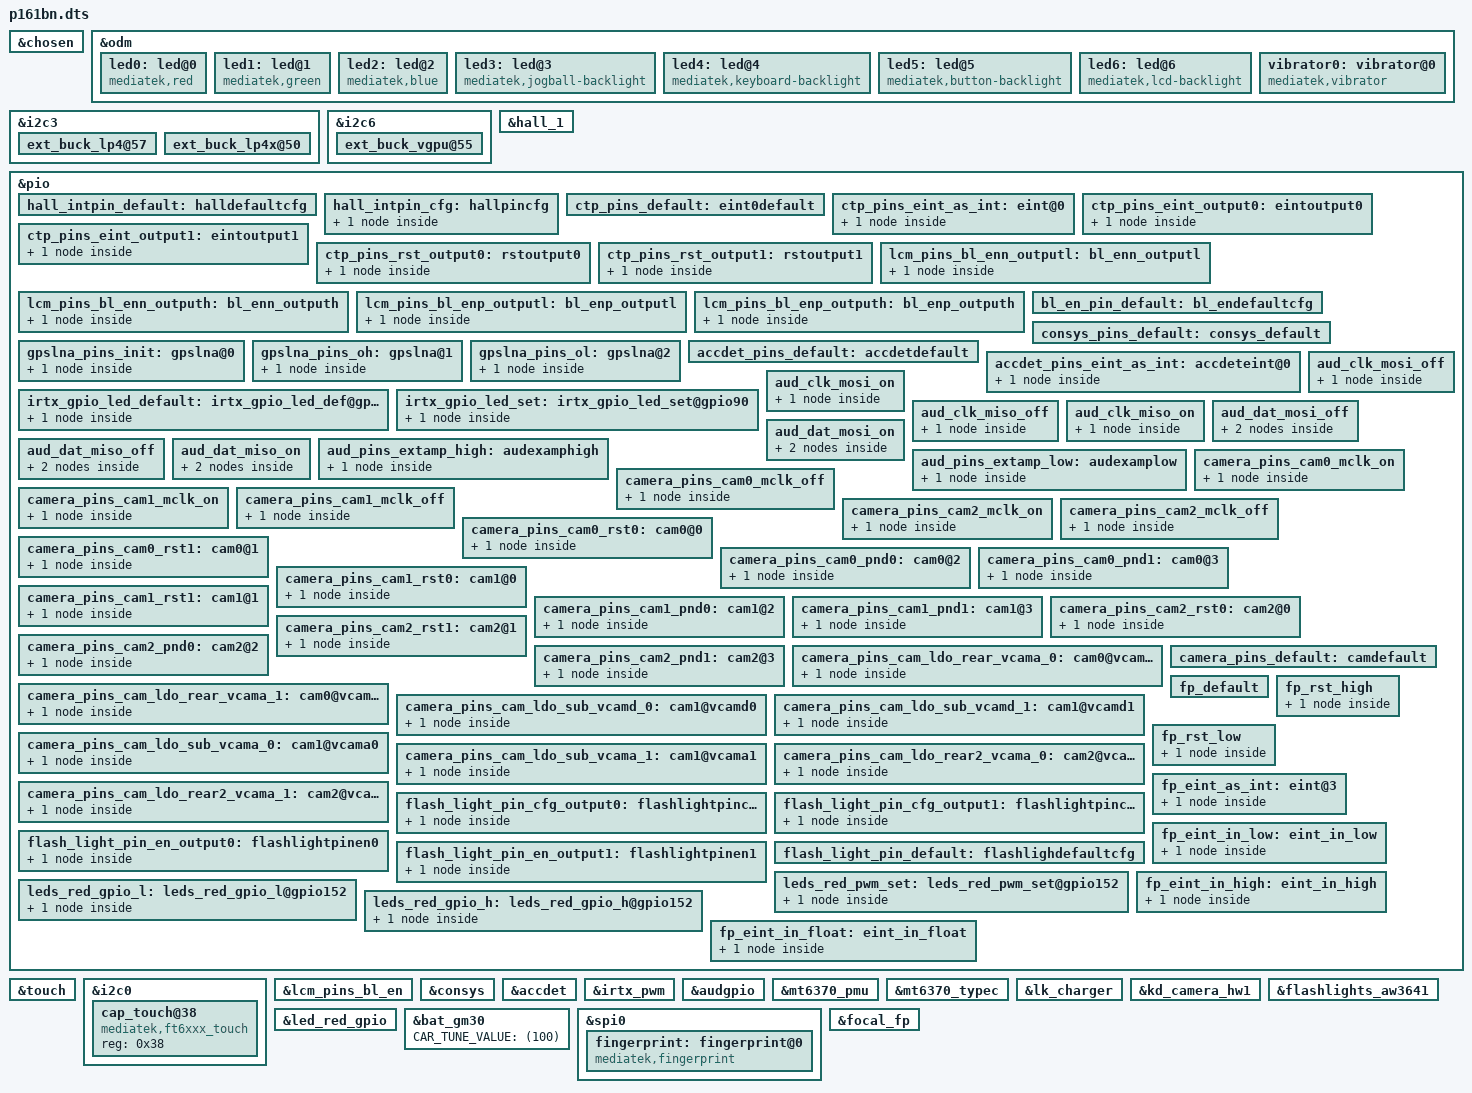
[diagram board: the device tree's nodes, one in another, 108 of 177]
#include <dt-bindings/interrupt-controller/arm-gic.h>
#include <dt-bindings/interrupt-controller/irq.h>
#include <dt-bindings/pinctrl/mt6765-pinfunc.h>
#include <dt-bindings/clock/mt6765-clk.h>

/dts-v1/;
/plugin/;

/* chosen */
&chosen {

	/* fpga may has no lk, we need to specify display info here */
	/* fb buffer is reserved using this dts by memory node above */
	atag,videolfb-fb_base_h = <0x0>;
	atag,videolfb-fb_base_l = <0x5e605000>;
	atag,videolfb-islcmfound = <1>;
	/* because no lk, so lcm is not inited */
	atag,videolfb-islcm_inited = <0>;
	atag,videolfb-fps= <6000>;
	atag,videolfb-vramSize= <0x017bb000>;
	atag,videolfb-lcmname= "nt35695B_fhd_dsi_cmd_auo_rt5081_drv";
};

&odm {
	led0:led@0 {
		compatible = "mediatek,red";
		led_mode = <1>;
		data = <2>;
		pwm_config = <0 0 0 0 0>;
	};
	led1:led@1 {
		compatible = "mediatek,green";
		led_mode = <3>;
		data = <2>;
		pwm_config = <0 0 0 0 0>;
	};
	led2:led@2 {
		compatible = "mediatek,blue";
		led_mode = <0>;
		data = <1>;
		pwm_config = <0 0 0 0 0>;
	};
	led3:led@3 {
		compatible = "mediatek,jogball-backlight";
		led_mode = <0>;
		data = <1>;
		pwm_config = <0 0 0 0 0>;
	};
	led4:led@4 {
		compatible = "mediatek,keyboard-backlight";
		led_mode = <0>;
		data = <1>;
		pwm_config = <0 0 0 0 0>;
	};
	led5:led@5 {
		compatible = "mediatek,button-backlight";
		led_mode = <0>;
		data = <1>;
		pwm_config = <0 0 0 0 0>;
	};
	led6:led@6 {
		compatible = "mediatek,lcd-backlight";
		led_mode = <5>;
		data = <1>;
		pwm_config = <0 0 0 0 0>;
	};
	vibrator0:vibrator@0 {
		compatible = "mediatek,vibrator";
		vib_timer = <25>;
		vib_limit = <9>;
		vib_vol= <9>; 			//1001 :2.8V,    1011 :3.0V,   1101 :3.3V
	};
};

&i2c3 {
	ext_buck_lp4@57 {
		regulator-name ="ext_buck_vdd2";
		regulator-min-microvolt = <300000>;
		regulator-max-microvolt = <1300000>;
		vsel_pin = <0>;
	};

	ext_buck_lp4x@50 {
		regulator-name ="ext_buck_vddq";
		regulator-min-microvolt = <300000>;
		regulator-max-microvolt = <1300000>;
		vsel_pin = <1>;
	};
};

&i2c6 {
	ext_buck_vgpu@55 {
		regulator-name ="ext_buck_vgpu";
		regulator-min-microvolt = <300000>;
		regulator-max-microvolt = <1300000>;
		vsel_pin = <2>;
	};
};


/*hall start*/

&hall_1 {
	pinctrl-names = "pin_default", "pin_cfg";
	pinctrl-0 = <&hall_intpin_default>;
	pinctrl-1 = <&hall_intpin_cfg>;
	status = "okay";
};
&pio {
	hall_intpin_default: halldefaultcfg {
	};
	hall_intpin_cfg: hallpincfg {
		pins_cmd_dat {
			pinmux = <PINMUX_GPIO9__FUNC_GPIO9>;
			slew-rate = <0>;
			bias-disable;
		};
	};
};
/*hall end*/

/* TOUCH start */
&touch {
	tpd-resolution = <720 1560>;
	use-tpd-button = <0>;
	tpd-key-num = <3>;
	tpd-key-local= <139 172 158 0>;
	tpd-key-dim-local = <90 883 100 40 230
				 883 100 40 370 883 100 40 0 0 0 0>;
	tpd-max-touch-num = <5>;
	tpd-filter-enable = <0>;
	tpd-filter-pixel-density = <146>;
	tpd-filter-custom-prameters = <0 0 0 0 0 0 0 0 0 0 0 0>;
	tpd-filter-custom-speed = <0 0 0>;
	pinctrl-names = "default", "state_eint_as_int", "state_eint_output0",
		"state_eint_output1", "state_rst_output0", "state_rst_output1";
	pinctrl-0 = <&ctp_pins_default>;
	pinctrl-1 = <&ctp_pins_eint_as_int>;
	pinctrl-2 = <&ctp_pins_eint_output0>;
	pinctrl-3 = <&ctp_pins_eint_output1>;
	pinctrl-4 = <&ctp_pins_rst_output0>;
	pinctrl-5 = <&ctp_pins_rst_output1>;
	status = "okay";
};
&pio {
	ctp_pins_default: eint0default {
	};
	ctp_pins_eint_as_int: eint@0 {
		pins_cmd_dat {
			pinmux = <PINMUX_GPIO0__FUNC_GPIO0>;
			slew-rate = <0>;
			bias-disable;
		};
	};
	ctp_pins_eint_output0: eintoutput0 {
		pins_cmd_dat {
			pinmux = <PINMUX_GPIO0__FUNC_GPIO0>;
			slew-rate = <1>;
			output-low;
		};
	};
	ctp_pins_eint_output1: eintoutput1 {
		pins_cmd_dat {
			pinmux = <PINMUX_GPIO0__FUNC_GPIO0>;
			slew-rate = <1>;
			output-high;
		};
	};
	ctp_pins_rst_output0: rstoutput0 {
		pins_cmd_dat {
			pinmux = <PINMUX_GPIO174__FUNC_GPIO174>;
			slew-rate = <1>;
			drive-strength = <MTK_DRIVE_16mA>;
			output-low;
		};
	};
	ctp_pins_rst_output1: rstoutput1 {
		pins_cmd_dat {
			pinmux = <PINMUX_GPIO174__FUNC_GPIO174>;
			slew-rate = <1>;
			output-high;
		};
	};
};

&i2c0 {
	cap_touch@38 {
		compatible = "mediatek,ft6xxx_touch";
		reg = <0x38>;
		status = "okay";
	};
};

/* TOUCH end */
&lcm_pins_bl_en {
	pinctrl-names = "bl_en_pin_default","lcm_enn_outputl","lcm_enn_outputh",
			"lcm_enp_outputl","lcm_enp_outputh";
	pinctrl-0 = <&bl_en_pin_default>;
	pinctrl-1 = <&lcm_pins_bl_enn_outputl>;
	pinctrl-2 = <&lcm_pins_bl_enn_outputh>;
	pinctrl-3 = <&lcm_pins_bl_enp_outputl>;
	pinctrl-4 = <&lcm_pins_bl_enp_outputh>;
	
	status = "okay";
};
&pio {
	lcm_pins_bl_enn_outputl: bl_enn_outputl {
		pins_cmd_dat {
			pinmux = <PINMUX_GPIO176__FUNC_GPIO176>;
			slew-rate = <1>;
			output-low;
		};
	};

	lcm_pins_bl_enn_outputh: bl_enn_outputh {
		pins_cmd_dat {
			pinmux = <PINMUX_GPIO176__FUNC_GPIO176>;
			slew-rate = <1>;
			output-high;
		};
	};
	lcm_pins_bl_enp_outputl: bl_enp_outputl {
		pins_cmd_dat {
			pinmux = <PINMUX_GPIO177__FUNC_GPIO177>;
			slew-rate = <1>;
			output-low;
		};
	};

	lcm_pins_bl_enp_outputh: bl_enp_outputh {
		pins_cmd_dat {
			pinmux = <PINMUX_GPIO177__FUNC_GPIO177>;
			slew-rate = <1>;
			output-high;
		};
	};
	
	bl_en_pin_default: bl_endefaultcfg {
	};
};

/* CONSYS GPIO standardization */
&pio {
	consys_pins_default: consys_default {
	};
	gpslna_pins_init: gpslna@0 {
		pins_cmd_dat {
			pinmux = <PINMUX_GPIO91__FUNC_GPIO91>;
			slew-rate = <0>;
			bias-disable;
			output-low;
		};
	};
	gpslna_pins_oh: gpslna@1 {
		pins_cmd_dat {
			pinmux = <PINMUX_GPIO91__FUNC_GPIO91>;
			slew-rate = <1>;
			output-high;
		};
	};
	gpslna_pins_ol: gpslna@2 {
		pins_cmd_dat {
			pinmux = <PINMUX_GPIO91__FUNC_GPIO91>;
			slew-rate = <1>;
			output-low;
		};
	};
};
&consys {
	pinctrl-names = "default", "gps_lna_state_init",
		"gps_lna_state_oh", "gps_lna_state_ol";
	pinctrl-0 = <&consys_pins_default>;
	pinctrl-1 = <&gpslna_pins_init>;
	pinctrl-2 = <&gpslna_pins_oh>;
	pinctrl-3 = <&gpslna_pins_ol>;
	status = "okay";
};
/* CONSYS end */

/* accdet start */
&accdet {
	accdet-mic-vol = <6>;
	headset-mode-setting = <0x500 0x500 1 0x1f0 0x800 0x800 0x20 0x44>;
	accdet-plugout-debounce = <1>;
	accdet-mic-mode = <1>;
	headset-eint-level-pol = <8>;
	headset-three-key-threshold = <0 80 220 400>;
	headset-three-key-threshold-CDD = <0 121 192 600>;
	headset-four-key-threshold = <0 58 121 192 400>;
	pinctrl-names = "default", "state_eint_as_int";
	pinctrl-0 = <&accdet_pins_default>;
	pinctrl-1 = <&accdet_pins_eint_as_int>;
	status = "okay";
};
&pio {
	accdet_pins_default: accdetdefault {
	};
	accdet_pins_eint_as_int: accdeteint@0 {
		pins_cmd_dat {
			pinmux = <PINMUX_GPIO9__FUNC_GPIO9>;
			slew-rate = <0>;
			bias-disable;
		};
	};
};
/* accdet end */


/* IRTX GPIO end */
&irtx_pwm {
	pinctrl-names = "irtx_gpio_led_default", "irtx_gpio_led_set";
	pinctrl-0 = <&irtx_gpio_led_default>;
	pinctrl-1 = <&irtx_gpio_led_set>;
	status = "okay";
};
&pio {
	irtx_gpio_led_default:irtx_gpio_led_def@gpio90 {
		pins_cmd_dat {
			pinmux = <PINMUX_GPIO90__FUNC_GPIO90>;
			slew-rate = <1>;
			bias-disable;
			output-low;
			input-schmitt-enable = <0>;
		};
	};

	irtx_gpio_led_set:irtx_gpio_led_set@gpio90 {
		pins_cmd_dat {
			pinmux = <PINMUX_GPIO90__FUNC_PWM0>;
			slew-rate = <1>;
			output-high;
		};
	};
};
/* IRTX GPIO Settings -End */

/* AUDIO GPIO standardization */
&audgpio {
	pinctrl-names = "aud_clk_mosi_off",
			"aud_clk_mosi_on",
			"aud_clk_miso_off",
			"aud_clk_miso_on",
			"aud_dat_mosi_off",
			"aud_dat_mosi_on",
			"aud_dat_miso_off",
			"aud_dat_miso_on",
			"extamp-pullhigh",
			"extamp-pulllow";
	pinctrl-0 = <&aud_clk_mosi_off>;
	pinctrl-1 = <&aud_clk_mosi_on>;
	pinctrl-2 = <&aud_clk_miso_off>;
	pinctrl-3 = <&aud_clk_miso_on>;
	pinctrl-4 = <&aud_dat_mosi_off>;
	pinctrl-5 = <&aud_dat_mosi_on>;
	pinctrl-6 = <&aud_dat_miso_off>;
	pinctrl-7 = <&aud_dat_miso_on>;
	pinctrl-8 = <&aud_pins_extamp_high>;
	pinctrl-9 = <&aud_pins_extamp_low>;
	status = "okay";
};

&pio {
	aud_clk_mosi_off: aud_clk_mosi_off {
		pins_cmd0_dat {
			pinmux = <PINMUX_GPIO136__FUNC_GPIO136>;
		};
	};

	aud_clk_mosi_on: aud_clk_mosi_on {
		pins_cmd0_dat {
			pinmux = <PINMUX_GPIO136__FUNC_AUD_CLK_MOSI>;
		};
	};

	aud_clk_miso_off: aud_clk_miso_off {
		pins_cmd0_dat {
			pinmux = <PINMUX_GPIO140__FUNC_GPIO140>;
		};
	};

	aud_clk_miso_on: aud_clk_miso_on {
		pins_cmd0_dat {
			pinmux = <PINMUX_GPIO140__FUNC_AUD_CLK_MISO>;
		};
	};

	aud_dat_mosi_off: aud_dat_mosi_off {
		pins_cmd1_dat {
			pinmux = <PINMUX_GPIO138__FUNC_GPIO138>;
			input-enable;
			slew-rate = <0>;
			bias-disable;
		};
		pins_cmd2_dat {
			pinmux = <PINMUX_GPIO139__FUNC_GPIO139>;
			input-enable;
			slew-rate = <0>;
			bias-disable;
		};
	};

	aud_dat_mosi_on: aud_dat_mosi_on {
		pins_cmd1_dat {
			pinmux = <PINMUX_GPIO138__FUNC_AUD_DAT_MOSI0>;
		};
		pins_cmd2_dat {
			pinmux = <PINMUX_GPIO139__FUNC_AUD_DAT_MOSI1>;
		};
	};

	aud_dat_miso_off: aud_dat_miso_off {
		pins_cmd1_dat {
			pinmux = <PINMUX_GPIO142__FUNC_GPIO142>;
			input-enable;
			slew-rate = <0>;
			bias-disable;
		};
		pins_cmd2_dat {
			pinmux = <PINMUX_GPIO143__FUNC_GPIO143>;
			input-enable;
			slew-rate = <0>;
			bias-disable;
		};
	};

	aud_dat_miso_on: aud_dat_miso_on {
		pins_cmd1_dat {
			pinmux = <PINMUX_GPIO142__FUNC_AUD_DAT_MISO0>;
		};
		pins_cmd2_dat {
			pinmux = <PINMUX_GPIO143__FUNC_AUD_DAT_MISO1>;
		};
	};

	aud_pins_extamp_high: audexamphigh {
		pins_cmd_dat {
			pinmux = <PINMUX_GPIO159__FUNC_GPIO159>;
			slew-rate = <1>;
			output-high;
		};
	};

	aud_pins_extamp_low: audexamplow {
		pins_cmd_dat {
			pinmux = <PINMUX_GPIO159__FUNC_GPIO159>;
			slew-rate = <1>;
			output-low;
		};
	};
};
/* AUDIO end */

&mt6370_pmu {
	mt6370,intr_gpio_num = <11>; /* direct defined GPIO num */
	mt6370,intr_gpio = <&pio 11 0x0>;
};

&mt6370_typec {
	mt6370pd,intr_gpio_num = <41>; /* direct defined GPIO num */
	mt6370pd,intr_gpio = <&pio 41 0x0>;
};

&lk_charger {
	fast_charge_voltage = <3000000>;
	/* charging current */
	usb_charger_current = <500000>;
	ac_charger_current = <550000>;
	ac_charger_input_current = <550000>;
	non_std_ac_charger_current = <550000>;
	charging_host_charger_current = <550000>;
	ta_ac_charger_current = <3000000>;
	pd_charger_current = <500000>;
//	enable_anime = <0>;

	/* battery temperature protection */
		temp_t4_threshold = <57>;
		temp_t3_threshold = <45>;
		temp_t1_threshold = <3>;
};

&pio {
	camera_pins_cam0_mclk_on: camera_pins_cam0_mclk_on {
		pins_cmd_dat {
			pinmux = <PINMUX_GPIO99__FUNC_CMMCLK0>;
		};
	};
	camera_pins_cam0_mclk_off: camera_pins_cam0_mclk_off {
		pins_cmd_dat {
			pinmux = <PINMUX_GPIO99__FUNC_GPIO99>;
		};
	};
	camera_pins_cam1_mclk_on: camera_pins_cam1_mclk_on {
		pins_cmd_dat {
			pinmux = <PINMUX_GPIO100__FUNC_CMMCLK1>;
		};
	};
	camera_pins_cam1_mclk_off: camera_pins_cam1_mclk_off {
		pins_cmd_dat {
			pinmux = <PINMUX_GPIO100__FUNC_GPIO100>;
		};
	};
	camera_pins_cam2_mclk_on: camera_pins_cam2_mclk_on {
		pins_cmd_dat {
			pinmux = <PINMUX_GPIO108__FUNC_CMMCLK2>;
		};
	};
	camera_pins_cam2_mclk_off: camera_pins_cam2_mclk_off {
		pins_cmd_dat {
			pinmux = <PINMUX_GPIO108__FUNC_GPIO108>;
		};
	};
	camera_pins_cam0_rst0: cam0@0 {
		pins_cmd_dat {
			pinmux = <PINMUX_GPIO101__FUNC_GPIO101>;
			slew-rate = <1>;
			output-low;
		};
	};
	camera_pins_cam0_rst1: cam0@1 {
		pins_cmd_dat {
			pinmux = <PINMUX_GPIO101__FUNC_GPIO101>;
			slew-rate = <1>;
			output-high;
		};
	};
	camera_pins_cam0_pnd0: cam0@2 {
		pins_cmd_dat {
			pinmux = <PINMUX_GPIO97__FUNC_GPIO97>;
			slew-rate = <1>;
			output-low;
		};
	};
	camera_pins_cam0_pnd1: cam0@3 {
		pins_cmd_dat {
			pinmux = <PINMUX_GPIO97__FUNC_GPIO97>;
			slew-rate = <1>;
			output-high;
		};
	};
	camera_pins_cam1_rst0: cam1@0 {
		pins_cmd_dat {
			pinmux = <PINMUX_GPIO102__FUNC_GPIO102>;
			slew-rate = <1>;
			output-low;
		};
	};
	camera_pins_cam1_rst1: cam1@1 {
		pins_cmd_dat {
			pinmux = <PINMUX_GPIO102__FUNC_GPIO102>;
			slew-rate = <1>;
			output-high;
		};
	};
	camera_pins_cam1_pnd0: cam1@2 {
		pins_cmd_dat {
			pinmux = <PINMUX_GPIO98__FUNC_GPIO98>;
			slew-rate = <1>;
			output-low;
		};
	};
	camera_pins_cam1_pnd1: cam1@3 {
		pins_cmd_dat {
			pinmux = <PINMUX_GPIO98__FUNC_GPIO98>;
			slew-rate = <1>;
			output-high;
		};
	};
	camera_pins_cam2_rst0: cam2@0 {
		pins_cmd_dat {
			pinmux = <PINMUX_GPIO109__FUNC_GPIO109>;
			slew-rate = <1>;
			output-low;
		};
	};
	camera_pins_cam2_rst1: cam2@1 {
		pins_cmd_dat {
			pinmux = <PINMUX_GPIO109__FUNC_GPIO109>;
			slew-rate = <1>;
			output-high;
		};
	};
	camera_pins_cam2_pnd0: cam2@2 {
		pins_cmd_dat {
			pinmux = <PINMUX_GPIO107__FUNC_GPIO107>;
			slew-rate = <1>;
			output-low;
		};
	};
	camera_pins_cam2_pnd1: cam2@3 {
		pins_cmd_dat {
			pinmux = <PINMUX_GPIO107__FUNC_GPIO107>;
			slew-rate = <1>;
			output-high;
		};
	};
	camera_pins_cam_ldo_rear_vcama_0: cam0@vcamd0 {
		pins_cmd_dat {
			pinmux = <PINMUX_GPIO168__FUNC_GPIO168>;
			slew-rate = <1>;
			output-low;
		};
	};
	camera_pins_cam_ldo_rear_vcama_1: cam0@vcamd1 {
		pins_cmd_dat {
			pinmux = <PINMUX_GPIO168__FUNC_GPIO168>;
			slew-rate = <1>;
			output-high;
		};
	};
	camera_pins_cam_ldo_sub_vcamd_0: cam1@vcamd0 {
		pins_cmd_dat {
			pinmux = <PINMUX_GPIO92__FUNC_GPIO92>;
			slew-rate = <1>;
			output-low;
		};
	};
	camera_pins_cam_ldo_sub_vcamd_1: cam1@vcamd1 {
		pins_cmd_dat {
			pinmux = <PINMUX_GPIO92__FUNC_GPIO92>;
			slew-rate = <1>;
			output-high;
		};
	};
	camera_pins_cam_ldo_sub_vcama_0: cam1@vcama0 {
		pins_cmd_dat {
			pinmux = <PINMUX_GPIO168__FUNC_GPIO168>;
			slew-rate = <1>;
			output-low;
		};
	};
	camera_pins_cam_ldo_sub_vcama_1: cam1@vcama1 {
		pins_cmd_dat {
			pinmux = <PINMUX_GPIO168__FUNC_GPIO168>;
			slew-rate = <1>;
			output-high;
		};
	};
	camera_pins_cam_ldo_rear2_vcama_0: cam2@vcama0 {
		pins_cmd_dat {
			pinmux = <PINMUX_GPIO168__FUNC_GPIO168>;
			slew-rate = <1>;
			output-low;
		};
	};
	camera_pins_cam_ldo_rear2_vcama_1: cam2@vcama1 {
		pins_cmd_dat {
			pinmux = <PINMUX_GPIO168__FUNC_GPIO168>;
			slew-rate = <1>;
			output-high;
		};
	};
	camera_pins_default: camdefault {
	};

};

&kd_camera_hw1 {
	pinctrl-names = "default",
			"cam0_rst0",
			"cam0_rst1",
			"cam0_pnd0",
			"cam0_pnd1",
			"cam1_rst0",
			"cam1_rst1",
			"cam1_pnd0",
			"cam1_pnd1",
			"cam2_rst0",
			"cam2_rst1",
			"cam2_pnd0",
			"cam2_pnd1",
			"cam0_vcama_on",
			"cam0_vcama_off",
			"cam1_vcamd_on",
			"cam1_vcamd_off",
			"cam1_vcama_on",
			"cam1_vcama_off",
			"cam2_vcama_on",
			"cam2_vcama_off",
			"cam0_mclk_on",
			"cam0_mclk_off",
			"cam1_mclk_on",
			"cam1_mclk_off",
			"cam2_mclk_on",
			"cam2_mclk_off";

	pinctrl-0 = <&camera_pins_default>;
	pinctrl-1 = <&camera_pins_cam0_rst0>;
	pinctrl-2 = <&camera_pins_cam0_rst1>;
	pinctrl-3 = <&camera_pins_cam0_pnd0>;
	pinctrl-4 = <&camera_pins_cam0_pnd1>;
	pinctrl-5 = <&camera_pins_cam1_rst0>;
	pinctrl-6 = <&camera_pins_cam1_rst1>;
	pinctrl-7 = <&camera_pins_cam1_pnd0>;
	pinctrl-8 = <&camera_pins_cam1_pnd1>;
	pinctrl-9 = <&camera_pins_cam2_rst0>;
	pinctrl-10 = <&camera_pins_cam2_rst1>;
	pinctrl-11 = <&camera_pins_cam2_pnd0>;
	pinctrl-12 = <&camera_pins_cam2_pnd1>;
	pinctrl-13 = <&camera_pins_cam_ldo_rear_vcama_1>;
	pinctrl-14 = <&camera_pins_cam_ldo_rear_vcama_0>;
	pinctrl-15 = <&camera_pins_cam_ldo_sub_vcamd_1>;
	pinctrl-16 = <&camera_pins_cam_ldo_sub_vcamd_0>;
	pinctrl-17 = <&camera_pins_cam_ldo_sub_vcama_1>;
	pinctrl-18 = <&camera_pins_cam_ldo_sub_vcama_0>;
	pinctrl-19 = <&camera_pins_cam_ldo_rear2_vcama_1>;
	pinctrl-20 = <&camera_pins_cam_ldo_rear2_vcama_0>;
	pinctrl-21 = <&camera_pins_cam0_mclk_on>;
	pinctrl-22 = <&camera_pins_cam0_mclk_off>;
	pinctrl-23 = <&camera_pins_cam1_mclk_on>;
	pinctrl-24 = <&camera_pins_cam1_mclk_off>;
	pinctrl-25 = <&camera_pins_cam2_mclk_on>;
	pinctrl-26 = <&camera_pins_cam2_mclk_off>;
	status = "okay";

};

/*add for aw3641 driver for camera flashlight*/
&pio {
        flash_light_pin_cfg_output0: flashlightpincfg0 {
            pins_cmd_dat {
                        pinmux = <PINMUX_GPIO153__FUNC_GPIO153>;
                        slew-rate = <1>;
                        output-low;
                };
        };
        flash_light_pin_cfg_output1: flashlightpincfg1 {
            pins_cmd_dat {
                        pinmux = <PINMUX_GPIO153__FUNC_GPIO153>;
                        slew-rate = <1>;
                        output-high;
                };
        };
        flash_light_pin_en_output0: flashlightpinen0 {
            pins_cmd_dat {
                        pinmux = <PINMUX_GPIO151__FUNC_GPIO151>;
                        slew-rate = <1>;
                        output-low;
                };
        };
        flash_light_pin_en_output1: flashlightpinen1 {
            pins_cmd_dat {
                        pinmux = <PINMUX_GPIO151__FUNC_GPIO151>;
                        slew-rate = <1>;
                        output-high;
                };
        };
         flash_light_pin_default: flashlighdefaultcfg {
        };

};

&flashlights_aw3641 {
        pinctrl-names = "flashlightpin_default", "flashlightpin_cfg0", "flashlightpin_cfg1","flashlightpin_en0","flashlightpin_en1";
        pinctrl-0 = <&flash_light_pin_default>;
        pinctrl-1 = <&flash_light_pin_cfg_output0>;
        pinctrl-2 = <&flash_light_pin_cfg_output1>;
        pinctrl-3 = <&flash_light_pin_en_output0>;
        pinctrl-4 = <&flash_light_pin_en_output1>;
        status = "okay";
};

&led_red_gpio {
 		pinctrl-names = "leds_red_pwm_set","leds_red_gpio_l","leds_red_gpio_h";
 		pinctrl-0 = <&leds_red_pwm_set>;
 		pinctrl-1 = <&leds_red_gpio_l>;
 		pinctrl-2 = <&leds_red_gpio_h>;
 		status = "okay";
	};
&pio {
 		leds_red_pwm_set:leds_red_pwm_set@gpio152 {
 			pins_cmd_dat {
 				pinmux = <PINMUX_GPIO152__FUNC_PWM2>;
 				slew-rate = <1>;
				output-high;
 			};
 		};
		leds_red_gpio_l:leds_red_gpio_l@gpio152 {
 			pins_cmd_dat {
 				pinmux = <PINMUX_GPIO152__FUNC_GPIO152>;
 				slew-rate = <1>;
				output-low;
 			};
 		};
    	leds_red_gpio_h:leds_red_gpio_h@gpio152 {
 			pins_cmd_dat {
				pinmux = <PINMUX_GPIO152__FUNC_GPIO152>;
				slew-rate = <1>;
 				output-high;
			};
 		};
	}; 

&bat_gm30{
CAR_TUNE_VALUE = <(100)>;
};
// TINNO BEGIN
// WJ add for fingerprint 20181008
&spi0 {
       fingerprint: fingerprint@0 { 
		compatible = "mediatek,fingerprint";
		spi-max-frequency = <10000000>;
		reg = <0x0>;
                interrupt-parent = <&pio>;
                interrupts = <3 IRQ_TYPE_EDGE_RISING 3 0>;
                status = "okay";
		clocks = <&topckgen CLK_TOP_SYSPLL3_D2>,
				<&topckgen CLK_TOP_SPI_SEL>,
				<&infracfg_ao CLK_IFR_SPI0>;
		clock-names = "parent-clk", "sel-clk", "spi-clk"; 
        }; 
}; 
&pio {
	fp_default: fp_default {
	};

	fp_rst_high: fp_rst_high {
		pins_cmd_dat {
			pinmux = <PINMUX_GPIO10__FUNC_GPIO10>;
			slew-rate = <1>;
			output-high;
		};
	};

	fp_rst_low: fp_rst_low {
		pins_cmd_dat {
			pinmux = <PINMUX_GPIO10__FUNC_GPIO10>;
			slew-rate = <1>;
			output-low;
		};
	};


	fp_eint_as_int: eint@3 {
		pins_cmd_dat {
			pinmux = <PINMUX_GPIO3__FUNC_GPIO3>;
			slew-rate = <0>;
			bias-disable;
		};
	};
	fp_eint_in_low: eint_in_low {
		pins_cmd_dat {
			pinmux = <PINMUX_GPIO3__FUNC_GPIO3>;
			slew-rate = <0>;
			bias-pull-down = <00>;
		};
	};
	fp_eint_in_high: eint_in_high {
		pins_cmd_dat {
			pinmux = <PINMUX_GPIO3__FUNC_GPIO3>;
			slew-rate = <0>;
			bias-pull-up = <00>;
		};
	};
	fp_eint_in_float: eint_in_float {
		pins_cmd_dat {
			pinmux = <PINMUX_GPIO3__FUNC_GPIO3>;
			slew-rate = <0>;
			bias-disable;
		};
	};
};

&fingerprint {
	pinctrl-names = "fp_default", "fp_rst_high", "fp_rst_low","eint_as_int", "eint_in_low", "eint_in_float", "eint_in_high";

	pinctrl-0 = <&fp_default>;
	pinctrl-1 = <&fp_rst_high>;
	pinctrl-2 = <&fp_rst_low>;
	pinctrl-3 = <&fp_eint_as_int>;
	pinctrl-4 = <&fp_eint_in_low>;
	pinctrl-5 = <&fp_eint_in_float>;
	pinctrl-6 = <&fp_eint_in_high>;
	status = "okay";

};
//add by lijian
&focal_fp {
	//compatible = "mediatek,focal_fp";
	pinctrl-names = "fp_rst_high", "fp_rst_low","eint_as_int", "eint_in_low", "eint_in_high";
	pinctrl-0 = <&fp_rst_high>;
	pinctrl-1 = <&fp_rst_low>;
	pinctrl-2 = <&fp_eint_as_int>;
	pinctrl-3 = <&fp_eint_in_low>;
	pinctrl-4 = <&fp_eint_in_high>;
	status = "okay";

};
// TINNO END
#include "bq24157.dtsi"

#include <p161bn/cust.dtsi>
/*End of this file, DO NOT ADD ANYTHING HERE*/
